VERSION "created by canmatrix"

NS_ :

BS_:

BU_: User ADM_PC_LL25 ADM_PC_BC25 ADM_PC_BP25 ADM_PC_BI25

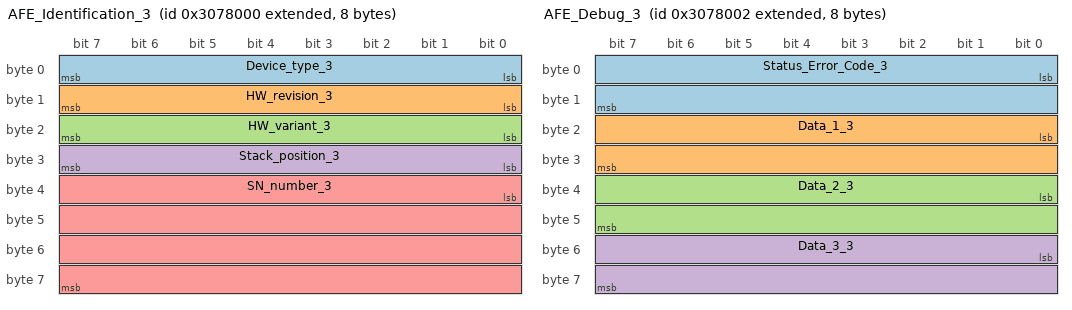
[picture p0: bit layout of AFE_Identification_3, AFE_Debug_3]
BO_ 2198306816 AFE_Identification_3: 8 ADM_PC_BP25
 SG_ Device_type_3 : 0|8@1+ (1,0) [0|255] "" Vector__XXX
 SG_ HW_revision_3 : 8|8@1+ (1,0) [0|255] "" Vector__XXX
 SG_ HW_variant_3 : 16|8@1+ (1,0) [0|255] "" Vector__XXX
 SG_ Stack_position_3 : 24|8@1+ (1,0) [0|255] "" Vector__XXX
 SG_ SN_number_3 : 32|32@1+ (1,0) [0|4294967295] "" Vector__XXX

BO_ 2198306817 AFE_FwInfo_3: 8 ADM_PC_BP25
 SG_ FW_info_mux_3 M : 56|8@1+ (1,0) [0|255] "" Vector__XXX
 SG_ FW_revision_0_3 m0 : 0|8@1+ (1,0) [0|255] "" Vector__XXX
 SG_ FW_revision_1_3 m0 : 8|8@1+ (1,0) [0|255] "" Vector__XXX
 SG_ FW_revision_2_3 m0 : 16|8@1+ (1,0) [0|255] "" Vector__XXX
 SG_ FW_revision_3_3 m0 : 24|8@1+ (1,0) [0|255] "" Vector__XXX
 SG_ FW_revision_4_3 m0 : 32|8@1+ (1,0) [0|255] "" Vector__XXX
 SG_ FW_revision_5_3 m0 : 40|8@1+ (1,0) [0|255] "" Vector__XXX
 SG_ FW_revision_6_3 m0 : 48|8@1+ (1,0) [0|255] "" Vector__XXX
 SG_ FW_revision_7_3 m1 : 0|8@1+ (1,0) [0|255] "" Vector__XXX
 SG_ FW_revision_8_3 m1 : 8|8@1+ (1,0) [0|255] "" Vector__XXX
 SG_ FW_revision_9_3 m1 : 16|8@1+ (1,0) [0|255] "" Vector__XXX
 SG_ FW_revision_10_3 m1 : 24|8@1+ (1,0) [0|255] "" Vector__XXX
 SG_ FW_revision_11_3 m1 : 32|8@1+ (1,0) [0|255] "" Vector__XXX
 SG_ FW_revision_12_3 m1 : 40|8@1+ (1,0) [0|255] "" Vector__XXX
 SG_ FW_revision_13_3 m1 : 48|8@1+ (1,0) [0|255] "" Vector__XXX
 SG_ FW_datecode_0_3 m2 : 0|8@1+ (1,0) [0|255] "" Vector__XXX
 SG_ FW_datecode_1_3 m2 : 8|8@1+ (1,0) [0|255] "" Vector__XXX
 SG_ FW_datecode_2_3 m2 : 16|8@1+ (1,0) [0|255] "" Vector__XXX
 SG_ FW_datecode_3_3 m2 : 24|8@1+ (1,0) [0|255] "" Vector__XXX
 SG_ FW_datecode_4_3 m2 : 32|8@1+ (1,0) [0|255] "" Vector__XXX
 SG_ FW_datecode_5_3 m2 : 40|8@1+ (1,0) [0|255] "" Vector__XXX
 SG_ FW_datecode_6_3 m2 : 48|8@1+ (1,0) [0|255] "" Vector__XXX
 SG_ FW_datecode_7_3 m3 : 0|8@1+ (1,0) [0|255] "" Vector__XXX
 SG_ FW_datecode_8_3 m3 : 8|8@1+ (1,0) [0|255] "" Vector__XXX
 SG_ FW_datecode_9_3 m3 : 16|8@1+ (1,0) [0|255] "" Vector__XXX
 SG_ FW_datecode_10_3 m3 : 24|8@1+ (1,0) [0|255] "" Vector__XXX
 SG_ FW_datecode_11_3 m3 : 32|8@1+ (1,0) [0|255] "" Vector__XXX
 SG_ FW_datecode_12_3 m3 : 40|8@1+ (1,0) [0|255] "" Vector__XXX
 SG_ FW_datecode_13_3 m3 : 48|8@1+ (1,0) [0|255] "" Vector__XXX

BO_ 2198306829 _AFE_Boot_FwInfo_3: 8 ADM_PC_BP25
 SG_ Boot_FW_info_mux_3 M : 56|8@1+ (1,0) [0|255] "" Vector__XXX
 SG_ FW_revision_0_3 m0 : 0|8@1+ (1,0) [0|255] "" Vector__XXX
 SG_ FW_revision_1_3 m0 : 8|8@1+ (1,0) [0|255] "" Vector__XXX
 SG_ FW_revision_2_3 m0 : 16|8@1+ (1,0) [0|255] "" Vector__XXX
 SG_ FW_revision_3_3 m0 : 24|8@1+ (1,0) [0|255] "" Vector__XXX
 SG_ FW_revision_4_3 m0 : 32|8@1+ (1,0) [0|255] "" Vector__XXX
 SG_ FW_revision_5_3 m0 : 40|8@1+ (1,0) [0|255] "" Vector__XXX
 SG_ FW_revision_6_3 m0 : 48|8@1+ (1,0) [0|255] "" Vector__XXX
 SG_ FW_revision_7_3 m1 : 0|8@1+ (1,0) [0|255] "" Vector__XXX
 SG_ FW_revision_8_3 m1 : 8|8@1+ (1,0) [0|255] "" Vector__XXX
 SG_ FW_revision_9_3 m1 : 16|8@1+ (1,0) [0|255] "" Vector__XXX
 SG_ FW_revision_10_3 m1 : 24|8@1+ (1,0) [0|255] "" Vector__XXX
 SG_ FW_revision_11_3 m1 : 32|8@1+ (1,0) [0|255] "" Vector__XXX
 SG_ FW_revision_12_3 m1 : 40|8@1+ (1,0) [0|255] "" Vector__XXX
 SG_ FW_revision_13_3 m1 : 48|8@1+ (1,0) [0|255] "" Vector__XXX
 SG_ FW_datecode_0_3 m2 : 0|8@1+ (1,0) [0|255] "" Vector__XXX
 SG_ FW_datecode_1_3 m2 : 8|8@1+ (1,0) [0|255] "" Vector__XXX
 SG_ FW_datecode_2_3 m2 : 16|8@1+ (1,0) [0|255] "" Vector__XXX
 SG_ FW_datecode_3_3 m2 : 24|8@1+ (1,0) [0|255] "" Vector__XXX
 SG_ FW_datecode_4_3 m2 : 32|8@1+ (1,0) [0|255] "" Vector__XXX
 SG_ FW_datecode_5_3 m2 : 40|8@1+ (1,0) [0|255] "" Vector__XXX
 SG_ FW_datecode_6_3 m2 : 48|8@1+ (1,0) [0|255] "" Vector__XXX
 SG_ FW_datecode_7_3 m3 : 0|8@1+ (1,0) [0|255] "" Vector__XXX
 SG_ FW_datecode_8_3 m3 : 8|8@1+ (1,0) [0|255] "" Vector__XXX
 SG_ FW_datecode_9_3 m3 : 16|8@1+ (1,0) [0|255] "" Vector__XXX
 SG_ FW_datecode_10_3 m3 : 24|8@1+ (1,0) [0|255] "" Vector__XXX
 SG_ FW_datecode_11_3 m3 : 32|8@1+ (1,0) [0|255] "" Vector__XXX
 SG_ FW_datecode_12_3 m3 : 40|8@1+ (1,0) [0|255] "" Vector__XXX
 SG_ FW_datecode_13_3 m3 : 48|8@1+ (1,0) [0|255] "" Vector__XXX

BO_ 2198306818 AFE_Debug_3: 8 ADM_PC_BP25
 SG_ Status_Error_Code_3 : 0|16@1+ (1,0) [0|65535] "" Vector__XXX
 SG_ Data_1_3 : 16|16@1+ (1,0) [0|65535] "" Vector__XXX
 SG_ Data_2_3 : 32|16@1+ (1,0) [0|65535] "" Vector__XXX
 SG_ Data_3_3 : 48|16@1+ (1,0) [0|65535] "" Vector__XXX

BO_ 2198306823 AFE_Status_3: 8 ADM_PC_BP25
 SG_ Running_3 : 0|1@1+ (1,0) [0|1] "" Vector__XXX
 SG_ PWM_3 : 1|1@1+ (1,0) [0|1] "" Vector__XXX
 SG_ Current_dc_loop_mode_3 : 2|1@1+ (1,0) [0|1] "" Vector__XXX
 SG_ Current_ac_loop_mode_3 : 3|1@1+ (1,0) [0|1] "" Vector__XXX
 SG_ Buck_3 : 5|1@1+ (1,0) [0|1] "" Vector__XXX
 SG_ Boost_3 : 6|1@1+ (1,0) [0|1] "" Vector__XXX
 SG_ Precharge_dc_buck_mode_3 : 7|1@1+ (1,0) [0|1] "" Vector__XXX
 SG_ Precharge_dc_boost_mode_3 : 8|1@1+ (1,0) [0|1] "" Vector__XXX
 SG_ Rectifier_3ph_3 : 9|1@1+ (1,0) [0|1] "" Vector__XXX
 SG_ Stack_mode_3 : 10|1@1+ (1,0) [0|1] "" Vector__XXX
 SG_ Master_3 : 11|1@1+ (1,0) [0|1] "" Vector__XXX
 SG_ Slave_3 : 12|1@1+ (1,0) [0|1] "" Vector__XXX
 SG_ Inverter_1ph_3 : 13|1@1+ (1,0) [0|1] "" Vector__XXX
 SG_ Boost_Neutral_3 : 14|1@1+ (1,0) [0|1] "" Vector__XXX
 SG_ Rectifier_1ph_3 : 15|1@1+ (1,0) [0|1] "" Vector__XXX
 SG_ Inverter_3ph_3 : 16|1@1+ (1,0) [0|1] "" Vector__XXX
 SG_ Ready_3 : 17|1@1+ (1,0) [0|1] "" Vector__XXX
 SG_ Inverter_1ph_Sync_3 : 18|1@1+ (1,0) [0|1] "" Vector__XXX
 SG_ Neutral_3 : 19|1@1+ (1,0) [0|1] "" Vector__XXX
 SG_ Rectifier_1ph_Buck_3 : 20|1@1+ (1,0) [0|1] "" Vector__XXX
 SG_ Inverter_1ph_Boost_3 : 21|1@1+ (1,0) [0|1] "" Vector__XXX
 SG_ Rectifier_distributed_3 : 22|1@1+ (1,0) [0|1] "" Vector__XXX
 SG_ MPPT_buck_3 : 23|1@1+ (1,0) [0|1] "" Vector__XXX
 SG_ MPPT_boost_3 : 24|1@1+ (1,0) [0|1] "" Vector__XXX
 SG_ Buck_2p_float_3 : 25|1@1+ (1,0) [0|1] "" Vector__XXX
 SG_ Inverter_1ph_Distributed_3 : 26|1@1+ (1,0) [0|1] "" Vector__XXX

BO_ 2198306822 AFE_Faults_3: 3 ADM_PC_BP25
 SG_ Protection_trip_internal_3 : 0|1@1+ (1,0) [0|1] "" Vector__XXX
 SG_ Protection_trip_external_3 : 1|1@1+ (1,0) [0|1] "" Vector__XXX
 SG_ Phase_U_overcurrent_3 : 2|1@1+ (1,0) [0|1] "" Vector__XXX
 SG_ Phase_U_overvoltage_3 : 3|1@1+ (1,0) [0|1] "" Vector__XXX
 SG_ Phase_U_undervoltage_3 : 4|1@1+ (1,0) [0|1] "" Vector__XXX
 SG_ Phase_V_overvoltage_3 : 5|1@1+ (1,0) [0|1] "" Vector__XXX
 SG_ Phase_V_undervoltage_3 : 6|1@1+ (1,0) [0|1] "" Vector__XXX
 SG_ Phase_V_overcurrent_3 : 7|1@1+ (1,0) [0|1] "" Vector__XXX
 SG_ Phase_W_overvoltage_3 : 8|1@1+ (1,0) [0|1] "" Vector__XXX
 SG_ Phase_W_undervoltage_3 : 9|1@1+ (1,0) [0|1] "" Vector__XXX
 SG_ Phase_W_overcurrent_3 : 10|1@1+ (1,0) [0|1] "" Vector__XXX
 SG_ DC_undervoltage_3 : 11|1@1+ (1,0) [0|1] "" Vector__XXX
 SG_ DC_overvoltage_3 : 12|1@1+ (1,0) [0|1] "" Vector__XXX
 SG_ MOSFET_overtemperature_3 : 13|1@1+ (1,0) [0|1] "" Vector__XXX
 SG_ Inductor_overtemperature_3 : 14|1@1+ (1,0) [0|1] "" Vector__XXX
 SG_ Keep_Alive_not_served_3 : 15|1@1+ (1,0) [0|1] "" Vector__XXX
 SG_ PLL_not_locked_3 : 16|1@1+ (1,0) [0|1] "" Vector__XXX
 SG_ NFO_3 : 20|1@1+ (1,0) [0|1] "" Vector__XXX
 SG_ Measurement_system_failure_3 : 21|1@1+ (1,0) [0|1] "" Vector__XXX
 SG_ EEPROM_failure_3 : 22|1@1+ (1,0) [0|1] "" Vector__XXX
 SG_ System_3 : 23|1@1+ (1,0) [0|1] "" Vector__XXX

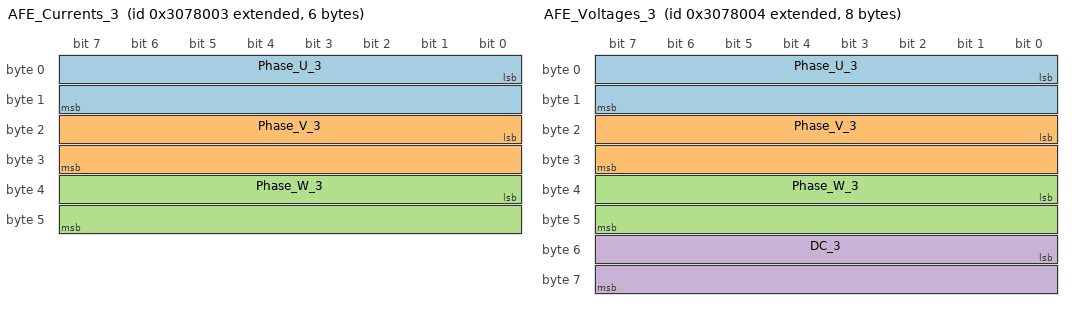
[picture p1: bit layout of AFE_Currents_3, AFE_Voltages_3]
BO_ 2198306819 AFE_Currents_3: 6 ADM_PC_BP25
 SG_ Phase_U_3 : 0|16@1- (0.01,0) [-327.68|327.67] "A" Vector__XXX
 SG_ Phase_V_3 : 16|16@1- (0.01,0) [-327.68|327.67] "A" Vector__XXX
 SG_ Phase_W_3 : 32|16@1- (0.01,0) [-327.68|327.67] "A" Vector__XXX

BO_ 2198306832 AFE_DC_Bus_current_3: 2 ADM_PC_BP25
 SG_ Bus_current_3 : 0|16@1- (0.01,0) [-327.68|327.67] "A" Vector__XXX

BO_ 2198306830 _AFE_Broadcast_3: 8 ADM_PC_BP25
 SG_ Diagnostics_Index_3 M : 56|8@1+ (1,0) [0|255] "" Vector__XXX
 SG_ Phase_U_3 m1 : 8|16@1- (0.01,0) [-327.68|327.67] "A" ADM_PC_BP25
 SG_ Phase_V_3 m1 : 24|16@1- (0.01,0) [-327.68|327.67] "A" ADM_PC_BP25
 SG_ Phase_W_3 m1 : 40|16@1- (0.01,0) [-327.68|327.67] "A" ADM_PC_BP25
 SG_ Stack_position_3 : 0|5@1+ (1,0) [0|31] "" ADM_PC_BP25
 SG_ Group_ID_3 : 5|3@1+ (1,0) [0|7] "" ADM_PC_BP25

BO_ 2198306820 AFE_Voltages_3: 8 ADM_PC_BP25
 SG_ Phase_U_3 : 0|16@1- (0.1,0) [-3276.8|3276.7] "V" Vector__XXX
 SG_ Phase_V_3 : 16|16@1- (0.1,0) [-3276.8|3276.7] "V" Vector__XXX
 SG_ Phase_W_3 : 32|16@1- (0.1,0) [-3276.8|3276.7] "V" Vector__XXX
 SG_ DC_3 : 48|16@1- (0.1,0) [-3276.8|3276.7] "V" Vector__XXX

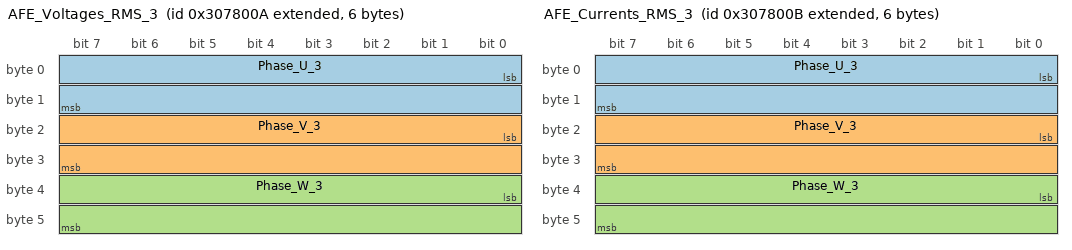
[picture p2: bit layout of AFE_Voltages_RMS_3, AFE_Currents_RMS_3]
BO_ 2198306826 AFE_Voltages_RMS_3: 6 ADM_PC_BP25
 SG_ Phase_U_3 : 0|16@1+ (0.1,0) [0|6553.5] "V" Vector__XXX
 SG_ Phase_V_3 : 16|16@1+ (0.1,0) [0|6553.5] "V" Vector__XXX
 SG_ Phase_W_3 : 32|16@1+ (0.1,0) [0|6553.5] "V" Vector__XXX

BO_ 2198306827 AFE_Currents_RMS_3: 6 ADM_PC_BP25
 SG_ Phase_U_3 : 0|16@1+ (0.01,0) [0.00|655.35] "A" Vector__XXX
 SG_ Phase_V_3 : 16|16@1+ (0.01,0) [0.00|655.35] "A" Vector__XXX
 SG_ Phase_W_3 : 32|16@1+ (0.01,0) [0.00|655.35] "A" Vector__XXX

BO_ 2198306828 AFE_Mains_3: 4 ADM_PC_BP25
 SG_ Frequency_3 : 0|16@1+ (0.01,0) [0.00|655.35] "Hz" Vector__XXX
 SG_ Phase_3 : 16|16@1- (0.1,0) [-3276.8|3276.7] "Deg." Vector__XXX

BO_ 2198306821 AFE_Temperatures_3: 4 ADM_PC_BP25
 SG_ Temp_Bridge_3 : 0|16@1- (0.01,0) [-327.68|327.67] "°C" Vector__XXX
 SG_ Temp_Inductors_3 : 16|16@1- (0.01,0) [-327.68|327.67] "°C" Vector__XXX

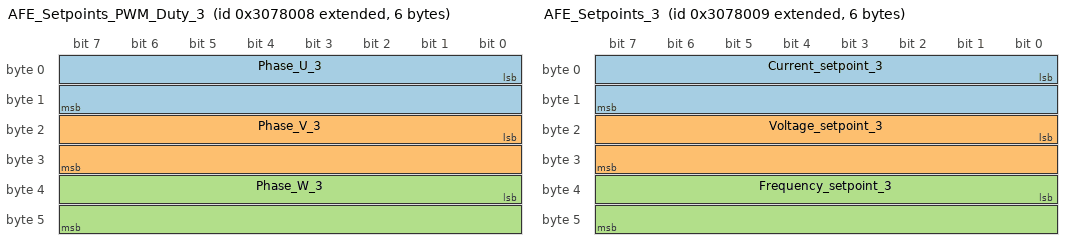
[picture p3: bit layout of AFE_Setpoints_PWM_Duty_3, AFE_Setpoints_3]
BO_ 2198306824 AFE_Setpoints_PWM_Duty_3: 6 ADM_PC_BP25
 SG_ Phase_U_3 : 0|16@1+ (0.001525902,0) [0E-009|99.999987570] "%" Vector__XXX
 SG_ Phase_V_3 : 16|16@1+ (0.001525902,0) [0E-009|99.999987570] "%" Vector__XXX
 SG_ Phase_W_3 : 32|16@1+ (0.001525902,0) [0E-009|99.999987570] "%" Vector__XXX

BO_ 2198306825 AFE_Setpoints_3: 6 ADM_PC_BP25
 SG_ Current_setpoint_3 : 0|16@1- (0.01,0) [-327.68|327.67] "A" Vector__XXX
 SG_ Voltage_setpoint_3 : 16|16@1+ (0.1,0) [0|6553.5] "V" Vector__XXX
 SG_ Frequency_setpoint_3 : 32|16@1+ (0.01,0) [0.00|655.35] "Hz" Vector__XXX

BO_ 2198274144 AFE_Keep_Alive_3: 1 User
 SG_ Keep_Alive_Enable_3 : 0|1@1+ (1,0) [0|1] "" ADM_PC_BP25

BO_ 2198274112 AFE_Mode_Control_3: 8 User
 SG_ Converter_ON_3 : 0|1@1+ (1,0) [0|1] "" ADM_PC_BP25
 SG_ PWM_ON_3 : 1|1@1+ (1,0) [0|1] "" ADM_PC_BP25
 SG_ DC_Current_feedback_ON_3 : 2|1@1+ (1,0) [0|1] "" ADM_PC_BP25
 SG_ AC_Current_feedback_ON_3 : 3|1@1+ (1,0) [0|1] "" ADM_PC_BP25
 SG_ Buck_ON_3 : 5|1@1+ (1,0) [0|1] "" ADM_PC_BP25
 SG_ Boost_ON_3 : 6|1@1+ (1,0) [0|1] "" ADM_PC_BP25
 SG_ Rectifier_3ph_ON_3 : 9|1@1+ (1,0) [0|1] "" ADM_PC_BP25
 SG_ Inverter_1ph_ON_3 : 10|1@1+ (1,0) [0|1] "" ADM_PC_BP25
 SG_ Rectifier_1ph_ON_3 : 11|1@1+ (1,0) [0|1] "" ADM_PC_BP25
 SG_ Boost_Neutral_ON_3 : 12|1@1+ (1,0) [0|1] "" ADM_PC_BP25
 SG_ Inverter_3ph_ON_3 : 13|1@1+ (1,0) [0|1] "" ADM_PC_BP25
 SG_ Inverter_1ph_Sync_ON_3 : 14|1@1+ (1,0) [0|1] "" ADM_PC_BP25
 SG_ Neutral_ON_3 : 15|1@1+ (1,0) [0|1] "" ADM_PC_BP25
 SG_ Rectifier_1ph_Buck_ON_3 : 16|1@1+ (1,0) [0|1] "" ADM_PC_BP25
 SG_ Inverter_1ph_Boost_ON_3 : 17|1@1+ (1,0) [0|1] "" ADM_PC_BP25
 SG_ Rectifier_Distributed_ON_3 : 18|1@1+ (1,0) [0|1] "" ADM_PC_BP25
 SG_ MPPT_buck_ON_3 : 19|1@1+ (1,0) [0|1] "" ADM_PC_BP25
 SG_ MPPT_boost_ON_3 : 20|1@1+ (1,0) [0|1] "" ADM_PC_BP25
 SG_ Buck_2p_float_ON_3 : 21|1@1+ (1,0) [0|1] "" ADM_PC_BP25
 SG_ Inverter_1ph_Distributed_ON_3 : 22|1@1+ (1,0) [0|1] "" ADM_PC_BP25

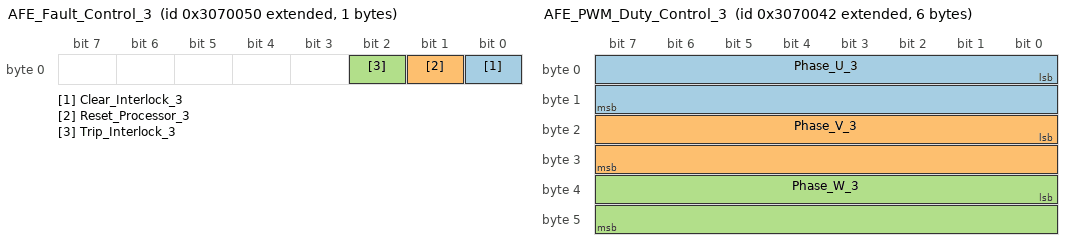
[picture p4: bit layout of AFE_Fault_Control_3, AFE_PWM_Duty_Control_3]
BO_ 2198274128 AFE_Fault_Control_3: 1 User
 SG_ Clear_Interlock_3 : 0|1@1+ (1,0) [0|1] "" ADM_PC_BP25
 SG_ Reset_Processor_3 : 1|1@1+ (1,0) [0|1] "" ADM_PC_BP25
 SG_ Trip_Interlock_3 : 2|1@1+ (1,0) [0|1] "" ADM_PC_BP25

BO_ 2198274113 AFE_Reactive_Current_Setpoint_Co: 2 User
 SG_ Reactive_current_setpoint_3 : 0|16@1- (0.01,0) [-150|150] "A" ADM_PC_BP25

BO_ 2198274114 AFE_PWM_Duty_Control_3: 6 User
 SG_ Phase_U_3 : 0|16@1+ (0.001525902,0) [0E-009|99.999987570] "%" ADM_PC_BP25
 SG_ Phase_V_3 : 16|16@1+ (0.001525902,0) [0E-009|99.999987570] "%" ADM_PC_BP25
 SG_ Phase_W_3 : 32|16@1+ (0.001525902,0) [0E-009|99.999987570] "%" ADM_PC_BP25

BO_ 2198274115 AFE_Current_Setpoint_Control_3: 2 User
 SG_ Current_setpoint_3 : 0|16@1- (0.01,0) [-150|150] "A" ADM_PC_BP25

BO_ 2198274116 AFE_Voltage_Setpoint_Control_3: 2 User
 SG_ Voltage_setpoint_3 : 0|16@1+ (0.1,0) [0|1500] "V" ADM_PC_BP25

BO_ 2198274120 AFE_Frequency_Setpoint_Control_3: 2 User
 SG_ Frequency_setpoint_3 : 0|16@1+ (0.01,0) [40|70] "Hz" ADM_PC_BP25

BO_ 2198274121 AFE_Phase_Setpoint_Control_3: 2 User
 SG_ Phase_setpoint_3 : 0|16@1+ (1,0) [0|360] "deg" ADM_PC_BP25

BO_ 2198274160 AFE_Rectifier_Setpoint_Control_3: 8 User
 SG_ Voltage_setpoint_2_3 : 0|16@1+ (0.1,0) [0|1500] "V" ADM_PC_BP25
 SG_ Current_setpoint_2_3 : 16|16@1- (0.01,0) [-150|150] "A" ADM_PC_BP25

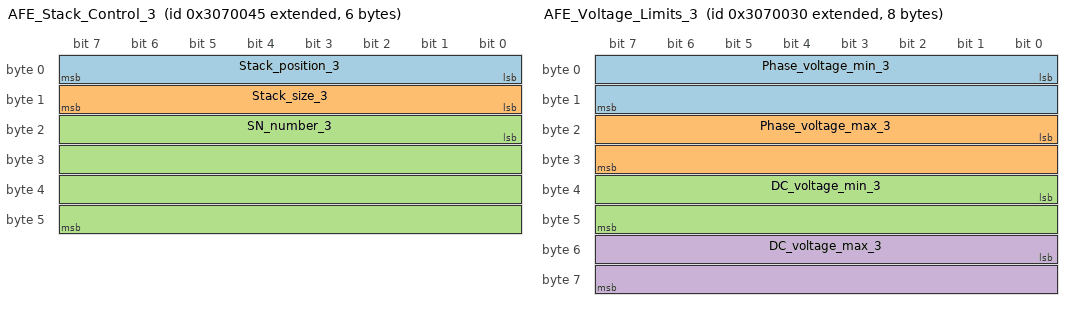
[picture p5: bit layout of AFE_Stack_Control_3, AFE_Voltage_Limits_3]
BO_ 2198274117 AFE_Stack_Control_3: 6 User
 SG_ Stack_position_3 : 0|8@1+ (1,0) [0|255] "" ADM_PC_BP25
 SG_ Stack_size_3 : 8|8@1+ (1,0) [0|255] "" ADM_PC_BP25
 SG_ SN_number_3 : 16|32@1+ (1,0) [0|4294967295] "" ADM_PC_BP25

BO_ 2198274096 AFE_Voltage_Limits_3: 8 User
 SG_ Phase_voltage_min_3 : 0|16@1- (0.1,0) [0|3276.7] "V" ADM_PC_BP25
 SG_ Phase_voltage_max_3 : 16|16@1- (0.1,0) [-3276.8|850] "V" ADM_PC_BP25
 SG_ DC_voltage_min_3 : 32|16@1- (0.1,0) [0|3276.7] "V" ADM_PC_BP25
 SG_ DC_voltage_max_3 : 48|16@1- (0.1,0) [-3276.8|850] "V" ADM_PC_BP25

BO_ 2198274097 AFE_Current_Limits_3: 4 User
 SG_ Phase_current_min_3 : 0|16@1- (0.01,0) [-60|60] "A" ADM_PC_BP25
 SG_ Phase_current_max_3 : 16|16@1- (0.01,0) [-60|60] "A" ADM_PC_BP25

BO_ 2198274124 AFE_Group_Control_3: 1 User
 SG_ Group_ID_3 : 0|8@1+ (1,0) [0|255] "" ADM_PC_BP25

BO_ 2198306831 AFE_Group_Info_3: 1 ADM_PC_BP25
 SG_ Group_ID_3 : 0|8@1+ (1,0) [0|255] "" Vector__XXX

BO_ 2198274145 AFE_System_Flags_Control_3: 8 User
 SG_ Factory_mode_3 : 0|1@1+ (1,0) [0|1] "" ADM_PC_BP25
 SG_ Silent_CAN_mode_3 : 1|1@1+ (1,0) [0|1] "" ADM_PC_BP25

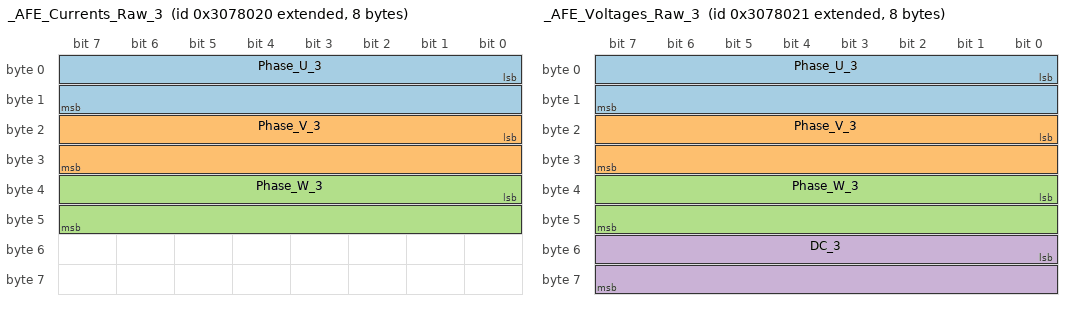
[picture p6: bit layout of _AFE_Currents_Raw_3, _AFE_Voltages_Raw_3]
BO_ 2198306848 _AFE_Currents_Raw_3: 8 ADM_PC_BP25
 SG_ Phase_U_3 : 0|16@1- (1,0) [-32768|32767] "" Vector__XXX
 SG_ Phase_V_3 : 16|16@1- (1,0) [-32768|32767] "" Vector__XXX
 SG_ Phase_W_3 : 32|16@1- (1,0) [-32768|32767] "" Vector__XXX

BO_ 2198306849 _AFE_Voltages_Raw_3: 8 ADM_PC_BP25
 SG_ Phase_U_3 : 0|16@1- (1,0) [-32768|32767] "" Vector__XXX
 SG_ Phase_V_3 : 16|16@1- (1,0) [-32768|32767] "" Vector__XXX
 SG_ Phase_W_3 : 32|16@1- (1,0) [-32768|32767] "" Vector__XXX
 SG_ DC_3 : 48|16@1- (1,0) [-32768|32767] "" Vector__XXX

BO_ 2198274122 _AFE_ADC_Calibration_Mode_3: 1 User
 SG_ Calibration_Index_3 M : 2|5@1+ (1,0) [0|31] "" Vector__XXX
 SG_ Current_U_3 m1 : 0|2@1+ (1,0) [0|3] "" ADM_PC_BP25
 SG_ Current_V_3 m2 : 0|2@1+ (1,0) [0|3] "" ADM_PC_BP25
 SG_ Current_W_3 m3 : 0|2@1+ (1,0) [0|3] "" ADM_PC_BP25
 SG_ Voltage_U_3 m4 : 0|2@1+ (1,0) [0|3] "" ADM_PC_BP25
 SG_ Voltage_V_3 m5 : 0|2@1+ (1,0) [0|3] "" ADM_PC_BP25
 SG_ Voltage_W_3 m6 : 0|2@1+ (1,0) [0|3] "" ADM_PC_BP25
 SG_ Voltage_DC_3 m7 : 0|2@1+ (1,0) [0|3] "" ADM_PC_BP25
 SG_ start_3 : 7|1@1+ (1,0) [0|1] "" ADM_PC_BP25

BO_ 2198274123 _AFE_ADC_Calibration_Setpoint_3: 3 User
 SG_ Calibration_Index_3 M : 16|5@1+ (1,0) [0|31] "" Vector__XXX
 SG_ Current_U_3 m1 : 0|16@1- (0.01,0) [-100|100] "A" ADM_PC_BP25
 SG_ Current_V_3 m2 : 0|16@1- (0.01,0) [-100|100] "A" ADM_PC_BP25
 SG_ Current_W_3 m3 : 0|16@1- (0.01,0) [-100|100] "A" ADM_PC_BP25
 SG_ Voltage_U_3 m4 : 0|16@1+ (0.1,0) [0|1500] "V" ADM_PC_BP25
 SG_ Voltage_V_3 m5 : 0|16@1+ (0.1,0) [0|1500] "V" ADM_PC_BP25
 SG_ Voltage_W_3 m6 : 0|16@1+ (0.1,0) [0|1500] "V" ADM_PC_BP25
 SG_ Voltage_DC_3 m7 : 0|16@1+ (0.1,0) [0|1500] "V" ADM_PC_BP25
 SG_ point_3 : 21|3@1+ (1,0) [0|7] "" ADM_PC_BP25

BO_ 2198274118 _AFE_Calibration_Offset_Update_3: 6 User
 SG_ Calibration_Index_3 M : 16|16@1+ (1,0) [0|65535] "" Vector__XXX
 SG_ Current_U_3 m0 : 0|16@1- (1,0) [-32768|32767] "ADC Counts" ADM_PC_BP25
 SG_ Current_V_3 m1 : 0|16@1- (1,0) [-32768|32767] "ADC Counts" ADM_PC_BP25
 SG_ Current_W_3 m2 : 0|16@1- (1,0) [-32768|32767] "ADC Counts" ADM_PC_BP25
 SG_ Voltage_U_3 m3 : 0|16@1- (1,0) [-32768|32767] "ADC Counts" ADM_PC_BP25
 SG_ Voltage_V_3 m4 : 0|16@1- (1,0) [-32768|32767] "ADC Counts" ADM_PC_BP25
 SG_ Voltage_W_3 m5 : 0|16@1- (1,0) [-32768|32767] "ADC Counts" ADM_PC_BP25
 SG_ Voltage_DC_3 m6 : 0|16@1- (1,0) [-32768|32767] "ADC Counts" ADM_PC_BP25
 SG_ CRC_3 : 32|16@1+ (1,0) [0|65535] "-" ADM_PC_BP25

BO_ 2198274119 _AFE_Calibration_Scale_Update_3: 6 User
 SG_ Calibration_Index_3 M : 16|16@1+ (1,0) [0|65535] "" Vector__XXX
 SG_ Current_U_3 m0 : 0|16@1- (0.0000152587890625,0) [-0.5000000000000000|0.4999847412109375] "scale = 1.0 + value" ADM_PC_BP25
 SG_ Current_V_3 m1 : 0|16@1- (0.0000152587890625,0) [-0.5000000000000000|0.4999847412109375] "scale = 1.0 + value" ADM_PC_BP25
 SG_ Current_W_3 m2 : 0|16@1- (0.0000152587890625,0) [-0.5000000000000000|0.4999847412109375] "scale = 1.0 + value" ADM_PC_BP25
 SG_ Voltage_U_3 m3 : 0|16@1- (0.0000152587890625,0) [-0.5000000000000000|0.4999847412109375] "scale = 1.0 + value" ADM_PC_BP25
 SG_ Voltage_V_3 m4 : 0|16@1- (0.0000152587890625,0) [-0.5000000000000000|0.4999847412109375] "scale = 1.0 + value" ADM_PC_BP25
 SG_ Voltage_W_3 m5 : 0|16@1- (0.0000152587890625,0) [-0.5000000000000000|0.4999847412109375] "scale = 1.0 + value" ADM_PC_BP25
 SG_ Voltage_DC_3 m6 : 0|16@1- (0.0000152587890625,0) [-0.5000000000000000|0.4999847412109375] "scale = 1.0 + value" ADM_PC_BP25
 SG_ CRC_3 : 32|16@1+ (1,0) [0|65535] "-" ADM_PC_BP25

BO_ 2198306897 _AFE_Calibration_Adc_Scale_3: 6 ADM_PC_BP25
 SG_ Adc_Index_3 M : 32|16@1+ (1,0) [0|65535] "" Vector__XXX
 SG_ Current_U_3 m0 : 0|32@1+ (1,0) [0|4294967295] "1 / adc_bins" User
 SG_ Current_V_3 m1 : 0|32@1+ (1,0) [0|4294967295] "1 / adc_bins" User
 SG_ Current_W_3 m2 : 0|32@1+ (1,0) [0|4294967295] "1 / adc_bins" User
 SG_ Voltage_U_3 m3 : 0|32@1+ (1,0) [0|4294967295] "1 / adc_bins" User
 SG_ Voltage_V_3 m4 : 0|32@1+ (1,0) [0|4294967295] "1 / adc_bins" User
 SG_ Voltage_W_3 m5 : 0|32@1+ (1,0) [0|4294967295] "1 / adc_bins" User
 SG_ Voltage_DC_3 m6 : 0|32@1+ (1,0) [0|4294967295] "1 / adc_bins" User

BO_ 2198306898 _AFE_Calibration_Adc_Fs_3: 6 ADM_PC_BP25
 SG_ Adc_Index_3 M : 32|16@1+ (1,0) [0|65535] "" Vector__XXX
 SG_ Current_U_3 m0 : 0|32@1+ (1,0) [0|4294967295] "Fullscale" User
 SG_ Current_V_3 m1 : 0|32@1+ (1,0) [0|4294967295] "Fullscale" User
 SG_ Current_W_3 m2 : 0|32@1+ (1,0) [0|4294967295] "Fullscale" User
 SG_ Voltage_U_3 m3 : 0|32@1+ (1,0) [0|4294967295] "Fullscale" User
 SG_ Voltage_V_3 m4 : 0|32@1+ (1,0) [0|4294967295] "Fullscale" User
 SG_ Voltage_W_3 m5 : 0|32@1+ (1,0) [0|4294967295] "Fullscale" User
 SG_ Voltage_DC_3 m6 : 0|32@1+ (1,0) [0|4294967295] "Fullscale" User

BO_ 2198306899 _AFE_Calibration_Adc_Offset_3: 4 ADM_PC_BP25
 SG_ Adc_Index_3 M : 16|16@1+ (1,0) [0|65535] "" Vector__XXX
 SG_ Current_U_3 m0 : 0|16@1- (1,0) [-32768|32767] "-" User
 SG_ Current_V_3 m1 : 0|16@1- (1,0) [-32768|32767] "-" User
 SG_ Current_W_3 m2 : 0|16@1- (1,0) [-32768|32767] "-" User
 SG_ Voltage_U_3 m3 : 0|16@1- (1,0) [-32768|32767] "-" User
 SG_ Voltage_V_3 m4 : 0|16@1- (1,0) [-32768|32767] "-" User
 SG_ Voltage_W_3 m5 : 0|16@1- (1,0) [-32768|32767] "-" User
 SG_ Voltage_DC_3 m6 : 0|16@1- (1,0) [-32768|32767] "-" User

BO_ 2198306900 _AFE_Calibration_Adc_Gain_3: 4 ADM_PC_BP25
 SG_ Adc_Index_3 M : 16|16@1+ (1,0) [0|65535] "" Vector__XXX
 SG_ Current_U_3 m0 : 0|16@1- (1,0) [-32768|32767] "-" User
 SG_ Current_V_3 m1 : 0|16@1- (1,0) [-32768|32767] "-" User
 SG_ Current_W_3 m2 : 0|16@1- (1,0) [-32768|32767] "-" User
 SG_ Voltage_U_3 m3 : 0|16@1- (1,0) [-32768|32767] "-" User
 SG_ Voltage_V_3 m4 : 0|16@1- (1,0) [-32768|32767] "-" User
 SG_ Voltage_W_3 m5 : 0|16@1- (1,0) [-32768|32767] "-" User
 SG_ Voltage_DC_3 m6 : 0|16@1- (1,0) [-32768|32767] "-" User

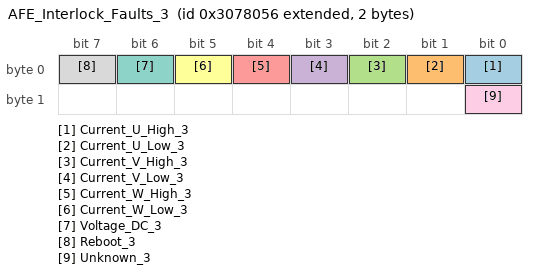
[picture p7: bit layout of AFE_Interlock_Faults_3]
BO_ 2198306902 AFE_Interlock_Faults_3: 2 ADM_PC_BP25
 SG_ Current_U_High_3 : 0|1@1+ (1,0) [0|1] "" Vector__XXX
 SG_ Current_U_Low_3 : 1|1@1+ (1,0) [0|1] "" Vector__XXX
 SG_ Current_V_High_3 : 2|1@1+ (1,0) [0|1] "" Vector__XXX
 SG_ Current_V_Low_3 : 3|1@1+ (1,0) [0|1] "" Vector__XXX
 SG_ Current_W_High_3 : 4|1@1+ (1,0) [0|1] "" Vector__XXX
 SG_ Current_W_Low_3 : 5|1@1+ (1,0) [0|1] "" Vector__XXX
 SG_ Voltage_DC_3 : 6|1@1+ (1,0) [0|1] "" Vector__XXX
 SG_ Reboot_3 : 7|1@1+ (1,0) [0|1] "" Vector__XXX
 SG_ Unknown_3 : 8|1@1+ (1,0) [0|1] "" Vector__XXX

BO_TX_BU_ 2198274112 : User,ADM_PC_LL25,ADM_PC_BC25,ADM_PC_BI25;
BO_TX_BU_ 2198274115 : User,ADM_PC_LL25,ADM_PC_BC25,ADM_PC_BI25;
BO_TX_BU_ 2198274116 : User,ADM_PC_LL25,ADM_PC_BC25,ADM_PC_BI25;
CM_ BO_ 2198306816  "Identification of the device";
CM_ BO_ 2198306817  "Git revision of the DSP firmware";
CM_ BO_ 2198306829  "Git revision of the bootloader firmware.";
CM_ BO_ 2198306818  "Values for debugging of HW/SW problems";
CM_ BO_ 2198306823  "Status bitfield";
CM_ BO_ 2198306822  "Fault bitfield";
CM_ BO_ 2198306819  "Current of phases U, V, W";
CM_ BO_ 2198306832  "Current of of the DC Bus";
CM_ BO_ 2198306830  "All AFEs will listen to this message";
CM_ BO_ 2198306827  "RMS Current of phases U, V, W";
CM_ BO_ 2198306828  "Three-Phase mains health (frequency, phase...)";
CM_ BO_ 2198306821  "Readouts of the module temperature sensors";
CM_ BO_ 2198306824  "Setpoints";
CM_ BO_ 2198306825  "Setpoints";
CM_ BO_ 2198274144  "Keep alive ping message. ";
CM_ BO_ 2198274112  "Operation Mode control: sets the converter operation mode";
CM_ BO_ 2198274128  "Fault Control: actions to clear faults and reset the system";
CM_ BO_ 2198274113  "Reactive power setpoint control.";
CM_ BO_ 2198274114  "PWM duty cycle control";
CM_ BO_ 2198274115  "Current setpoint control";
CM_ BO_ 2198274116  "Voltage setpoint control";
CM_ BO_ 2198274120  "Frequency setpoint control";
CM_ BO_ 2198274121  "Phase setpoint control";
CM_ BO_ 2198274160  "Additional voltage and current setpoints in single-phase rectifier and inverter control modes.";
CM_ BO_ 2198274117  "PFC stack control";
CM_ BO_ 2198274096  "Set the input and output voltage limits (minimum and maximum)";
CM_ BO_ 2198274097  "Set the output current limits (mminimum and maximum)";
CM_ BO_ 2198274124  "Set the Group ID of the device";
CM_ BO_ 2198306831  "Contains the Group ID of the device";
CM_ BO_ 2198274145  "Control the system flags";
CM_ BO_ 2198306848  "Current of phases A and B";
CM_ BO_ 2198306849  "Current of phases A and B";
CM_ BO_ 2198274122  "Automatic ADC calibration.";
CM_ BO_ 2198274123  "Setpoint for automatic ADC calibration.";
CM_ BO_ 2198274118  "Update of the calibration table for offsets.";
CM_ BO_ 2198274119  "Update of the calibration table for scales.";
CM_ BO_ 2198306897  "
                Adc scale (resolution) value of readouts.
            ";
CM_ BO_ 2198306898  "
                Adc fullscale value of readouts.
            ";
CM_ BO_ 2198306899  "
                Readout of ADC calibration data (offset) from EEPROM.
            ";
CM_ BO_ 2198306900  "
                Readout of ADC calibration data (gain) from EEPROM.
            ";
CM_ BO_ 2198306902  "Fault bitfield";

CM_ SG_ 2198306816 Device_type_3 "The device identification field, uniquely identifies the sender in the network";
CM_ SG_ 2198306816 HW_revision_3 "The hardware revision number";
CM_ SG_ 2198306816 HW_variant_3 "The DSP firmware revision number";
CM_ SG_ 2198306816 Stack_position_3 "Position of the module within the stack";
CM_ SG_ 2198306816 SN_number_3 "Unique module serial number";
CM_ SG_ 2198306817 FW_revision_0_3 "Character 0";
CM_ SG_ 2198306817 FW_revision_1_3 "Character 1";
CM_ SG_ 2198306817 FW_revision_2_3 "Character 2";
CM_ SG_ 2198306817 FW_revision_3_3 "Character 3";
CM_ SG_ 2198306817 FW_revision_4_3 "Character 3";
CM_ SG_ 2198306817 FW_revision_5_3 "Character 3";
CM_ SG_ 2198306817 FW_revision_6_3 "Character 3";
CM_ SG_ 2198306817 FW_revision_7_3 "Character 7";
CM_ SG_ 2198306817 FW_revision_8_3 "Character 8";
CM_ SG_ 2198306817 FW_revision_9_3 "Character 9";
CM_ SG_ 2198306817 FW_revision_10_3 "Character 10";
CM_ SG_ 2198306817 FW_revision_11_3 "Character 11";
CM_ SG_ 2198306817 FW_revision_12_3 "Character 12";
CM_ SG_ 2198306817 FW_revision_13_3 "Character 13";
CM_ SG_ 2198306817 FW_datecode_0_3 "Character 0";
CM_ SG_ 2198306817 FW_datecode_1_3 "Character 1";
CM_ SG_ 2198306817 FW_datecode_2_3 "Character 2";
CM_ SG_ 2198306817 FW_datecode_3_3 "Character 3";
CM_ SG_ 2198306817 FW_datecode_4_3 "Character 3";
CM_ SG_ 2198306817 FW_datecode_5_3 "Character 3";
CM_ SG_ 2198306817 FW_datecode_6_3 "Character 3";
CM_ SG_ 2198306817 FW_datecode_7_3 "Character 7";
CM_ SG_ 2198306817 FW_datecode_8_3 "Character 8";
CM_ SG_ 2198306817 FW_datecode_9_3 "Character 9";
CM_ SG_ 2198306817 FW_datecode_10_3 "Character 10";
CM_ SG_ 2198306817 FW_datecode_11_3 "Character 11";
CM_ SG_ 2198306817 FW_datecode_12_3 "Character 12";
CM_ SG_ 2198306817 FW_datecode_13_3 "Character 13";
CM_ SG_ 2198306829 FW_revision_0_3 "Character 0";
CM_ SG_ 2198306829 FW_revision_1_3 "Character 1";
CM_ SG_ 2198306829 FW_revision_2_3 "Character 2";
CM_ SG_ 2198306829 FW_revision_3_3 "Character 3";
CM_ SG_ 2198306829 FW_revision_4_3 "Character 3";
CM_ SG_ 2198306829 FW_revision_5_3 "Character 3";
CM_ SG_ 2198306829 FW_revision_6_3 "Character 3";
CM_ SG_ 2198306829 FW_revision_7_3 "Character 7";
CM_ SG_ 2198306829 FW_revision_8_3 "Character 8";
CM_ SG_ 2198306829 FW_revision_9_3 "Character 9";
CM_ SG_ 2198306829 FW_revision_10_3 "Character 10";
CM_ SG_ 2198306829 FW_revision_11_3 "Character 11";
CM_ SG_ 2198306829 FW_revision_12_3 "Character 12";
CM_ SG_ 2198306829 FW_revision_13_3 "Character 13";
CM_ SG_ 2198306829 FW_datecode_0_3 "Character 0";
CM_ SG_ 2198306829 FW_datecode_1_3 "Character 1";
CM_ SG_ 2198306829 FW_datecode_2_3 "Character 2";
CM_ SG_ 2198306829 FW_datecode_3_3 "Character 3";
CM_ SG_ 2198306829 FW_datecode_4_3 "Character 3";
CM_ SG_ 2198306829 FW_datecode_5_3 "Character 3";
CM_ SG_ 2198306829 FW_datecode_6_3 "Character 3";
CM_ SG_ 2198306829 FW_datecode_7_3 "Character 7";
CM_ SG_ 2198306829 FW_datecode_8_3 "Character 8";
CM_ SG_ 2198306829 FW_datecode_9_3 "Character 9";
CM_ SG_ 2198306829 FW_datecode_10_3 "Character 10";
CM_ SG_ 2198306829 FW_datecode_11_3 "Character 11";
CM_ SG_ 2198306829 FW_datecode_12_3 "Character 12";
CM_ SG_ 2198306829 FW_datecode_13_3 "Character 13";
CM_ SG_ 2198306818 Status_Error_Code_3 "Main status / error code as defined in errno/errno.h";
CM_ SG_ 2198306818 Data_1_3 "Additional information for the error/status";
CM_ SG_ 2198306818 Data_2_3 "Additional information for the error/status";
CM_ SG_ 2198306818 Data_3_3 "Additional information for the error/status";
CM_ SG_ 2198306823 Running_3 "Indicates if converter is running.";
CM_ SG_ 2198306823 PWM_3 "Indicates if converter is in PWM control mode.";
CM_ SG_ 2198306823 Current_dc_loop_mode_3 "Indicates if the current DC loop is enabled.";
CM_ SG_ 2198306823 Current_ac_loop_mode_3 "Indicates if the current AC loop is enabled.";
CM_ SG_ 2198306823 Buck_3 "Indicates if converter is in buck control mode.";
CM_ SG_ 2198306823 Boost_3 "Indicates if converter is in boost control mode.";
CM_ SG_ 2198306823 Precharge_dc_buck_mode_3 "Indicates if the precharge DC mode is enabled - buck direction.";
CM_ SG_ 2198306823 Precharge_dc_boost_mode_3 "Indicates if the precharge DC mode is enabled - boost direction.";
CM_ SG_ 2198306823 Rectifier_3ph_3 "Indicates if converter is in three-phase rectifier control mode.";
CM_ SG_ 2198306823 Stack_mode_3 "Indicates if converter is operating in stack mode.";
CM_ SG_ 2198306823 Master_3 "Indicates if converter is master in the stack.";
CM_ SG_ 2198306823 Slave_3 "Indicates if converter is slave in the stack.";
CM_ SG_ 2198306823 Inverter_1ph_3 "Indicates if converter is in single-phase inverter control mode.";
CM_ SG_ 2198306823 Boost_Neutral_3 "Indicates if converter is in boost control mode with neutral generation.";
CM_ SG_ 2198306823 Rectifier_1ph_3 "Indicates if converter is in single-phase rectifier control mode.";
CM_ SG_ 2198306823 Inverter_3ph_3 "Indicates if converter is in three-phase inverter control mode.";
CM_ SG_ 2198306823 Ready_3 "Indicates if converter is ready for operation.";
CM_ SG_ 2198306823 Inverter_1ph_Sync_3 "Single-phase inverter control mode with phase synchronization.";
CM_ SG_ 2198306823 Neutral_3 "Open-loop neutral generation.";
CM_ SG_ 2198306823 Rectifier_1ph_Buck_3 "Single-phase rectifier with buck on one leg.";
CM_ SG_ 2198306823 Inverter_1ph_Boost_3 "Single-phase inverter with boost on one leg.";
CM_ SG_ 2198306823 Rectifier_distributed_3 "Not available at the moment";
CM_ SG_ 2198306823 MPPT_buck_3 "Not available at the moment";
CM_ SG_ 2198306823 MPPT_boost_3 "Not available at the moment";
CM_ SG_ 2198306823 Buck_2p_float_3 "Buck in phases L1 and L2. Phase L3 is left floating (high impedance)";
CM_ SG_ 2198306823 Inverter_1ph_Distributed_3 "Single-phase inverter mode  distributed";
CM_ SG_ 2198306822 Protection_trip_internal_3 "This flagg is asserted if the interlock is open due to an internal fault condition (self-protection)";
CM_ SG_ 2198306822 Protection_trip_external_3 "This flag is asserted if the interlock is open due to an external condition received in the module.";
CM_ SG_ 2198306822 Phase_U_overcurrent_3 "Indicates an overcurrent event on Phase U. The overcurrent event is triggered when the measured phase current is over the programmed current limit.";
CM_ SG_ 2198306822 Phase_U_overvoltage_3 "Indicates an overvoltage event on Phase U. The overvoltage event is triggered when the measured phase voltage is over the programmed voltage limit.";
CM_ SG_ 2198306822 Phase_U_undervoltage_3 "Indicates an undervoltage event on Phase U. The overvoltage event is triggered when the measured phase voltage is over the programmed voltage limit.";
CM_ SG_ 2198306822 Phase_V_overvoltage_3 "Indicates an overvoltage event on Phase V. The overvoltage event is triggered when the measured phase voltage is over the programmed voltage limit.";
CM_ SG_ 2198306822 Phase_V_undervoltage_3 "Indicates an undervoltage event on Phase U. The overvoltage event is triggered when the measured phase voltage is over the programmed voltage limit.";
CM_ SG_ 2198306822 Phase_V_overcurrent_3 "Indicates an overcurrent event on Phase U. The overcurrent event is triggered when the measured phase current is over the programmed current limit.";
CM_ SG_ 2198306822 Phase_W_overvoltage_3 "Indicates an overvoltage event on Phase U. The overvoltage event is triggered when the measured phase voltage is over the programmed voltage limit.";
CM_ SG_ 2198306822 Phase_W_undervoltage_3 "Indicates an undervoltage event on Phase U. The overvoltage event is triggered when the measured phase voltage is over the programmed voltage limit.";
CM_ SG_ 2198306822 Phase_W_overcurrent_3 "Indicates an overcurrent event on Phase U. The overcurrent event is triggered when the measured phase current is over the programmed current limit.";
CM_ SG_ 2198306822 DC_undervoltage_3 "DC bus undervoltage condition. The undervoltage condition is asserted when the measured dc bus voltage is under the programmed voltage limit.";
CM_ SG_ 2198306822 DC_overvoltage_3 "DC bus overvoltage condition. The overvoltage condition is asserted when the measured dc bus voltage is over the programmed voltage limit.";
CM_ SG_ 2198306822 MOSFET_overtemperature_3 "This flag is asserted when the temperature of the MOSFET block is too high.";
CM_ SG_ 2198306822 Inductor_overtemperature_3 "This flag is asserted when the temperature of the inductor block is too high.";
CM_ SG_ 2198306822 Keep_Alive_not_served_3 "The Keep Alive feature is enabled but it was not served with the periodic message.";
CM_ SG_ 2198306822 PLL_not_locked_3 "Flag asserted when in rectifier modes, the PLL went out of lock condition";
CM_ SG_ 2198306822 Measurement_system_failure_3 "The voltages/currents measurement system is malfunctionning, and readouts are not guaranteed to be accurate.";
CM_ SG_ 2198306822 EEPROM_failure_3 "The configuration EEPROM failed to load or save the module configuration.";
CM_ SG_ 2198306819 Phase_U_3 "Phase current is the MOSFET loop current, in the branch U of the converter.";
CM_ SG_ 2198306819 Phase_V_3 "Phase current is the MOSFET loop current, in the branch V of the converter.";
CM_ SG_ 2198306819 Phase_W_3 "Phase current is the MOSFET loop current, in the branch W of the converter.";
CM_ SG_ 2198306832 Bus_current_3 "DC Bus current is possitive when current goes from input to output";
CM_ SG_ 2198306830 Phase_U_3 "Phase current is the MOSFET loop current, in the branch U of the converter.";
CM_ SG_ 2198306830 Phase_V_3 "Phase current is the MOSFET loop current, in the branch V of the converter.";
CM_ SG_ 2198306830 Phase_W_3 "Phase current is the MOSFET loop current, in the branch W of the converter.";
CM_ SG_ 2198306830 Stack_position_3 "Sender Stack position";
CM_ SG_ 2198306830 Group_ID_3 "Sender Group ID";
CM_ SG_ 2198306827 Phase_U_3 "RMS Phase current is the MOSFET loop current, in the branch U of the converter.";
CM_ SG_ 2198306827 Phase_V_3 "RMS Phase current is the MOSFET loop current, in the branch V of the converter.";
CM_ SG_ 2198306827 Phase_W_3 "RMS Phase current is the MOSFET loop current, in the branch W of the converter.";
CM_ SG_ 2198306828 Frequency_3 "Frequency of Three-Phase system";
CM_ SG_ 2198306828 Phase_3 "Phase of Three-Phase system";
CM_ SG_ 2198306821 Temp_Bridge_3 "Temperature of the MOSFET block";
CM_ SG_ 2198306821 Temp_Inductors_3 "Temperature of the inductors";
CM_ SG_ 2198306824 Phase_U_3 "The actual PWM duty cycle setpoint";
CM_ SG_ 2198306824 Phase_V_3 "The actual PWM duty cycle setpoint";
CM_ SG_ 2198306824 Phase_W_3 "The actual PWM duty cycle setpoint";
CM_ SG_ 2198306825 Current_setpoint_3 "The actual current setpoint";
CM_ SG_ 2198306825 Voltage_setpoint_3 "The actual voltage setpoint";
CM_ SG_ 2198306825 Frequency_setpoint_3 "The actual frequency setpoint";
CM_ SG_ 2198274144 Keep_Alive_Enable_3 "If set to 1, module will expect to receive this message every second repeatedly, or it will stop operation";
CM_ SG_ 2198274112 Converter_ON_3 "Enable the converter.";
CM_ SG_ 2198274112 PWM_ON_3 "Enable the PWM control mode.";
CM_ SG_ 2198274112 DC_Current_feedback_ON_3 "Enable the DC current loop";
CM_ SG_ 2198274112 AC_Current_feedback_ON_3 "Enable the AC current loop";
CM_ SG_ 2198274112 Buck_ON_3 "Enable the buck control mode.";
CM_ SG_ 2198274112 Boost_ON_3 "Enable the boost control mode.";
CM_ SG_ 2198274112 Rectifier_3ph_ON_3 "Enable the three-phase rectifier control mode.";
CM_ SG_ 2198274112 Inverter_1ph_ON_3 "Enable the single-phase inverter control mode.";
CM_ SG_ 2198274112 Rectifier_1ph_ON_3 "Enable the single-phase rectifier control mode.";
CM_ SG_ 2198274112 Boost_Neutral_ON_3 "Enable the boost control mode with neutral generation.";
CM_ SG_ 2198274112 Inverter_3ph_ON_3 "Enable the three-phase inverter control mode.";
CM_ SG_ 2198274112 Inverter_1ph_Sync_ON_3 "Single-phase inverter control mode with phase synchronization.";
CM_ SG_ 2198274112 Neutral_ON_3 "Open-loop neutral generation.";
CM_ SG_ 2198274112 Rectifier_1ph_Buck_ON_3 "Single-phase rectifier with buck on one leg.";
CM_ SG_ 2198274112 Inverter_1ph_Boost_ON_3 "Single-phase inverter with boost on one leg.";
CM_ SG_ 2198274112 Rectifier_Distributed_ON_3 "Single-phase (floating) distributed rectifier";
CM_ SG_ 2198274112 MPPT_buck_ON_3 "MPPT buck";
CM_ SG_ 2198274112 MPPT_boost_ON_3 "MPPT boost";
CM_ SG_ 2198274112 Buck_2p_float_ON_3 "Boost on L1 and L2. Floating L3 (high-impedance)";
CM_ SG_ 2198274112 Inverter_1ph_Distributed_ON_3 "Single-phase inverter mode distributed";
CM_ SG_ 2198274128 Clear_Interlock_3 "Clears the converter interlock";
CM_ SG_ 2198274128 Reset_Processor_3 "Reset the converter DSP";
CM_ SG_ 2198274128 Trip_Interlock_3 "Trip the inetrnal Interlock";
CM_ SG_ 2198274113 Reactive_current_setpoint_3 "This defines reactive current setpoint for 3-phase rectifier mode";
CM_ SG_ 2198274114 Phase_U_3 "The actual PWM duty cycle setpoint";
CM_ SG_ 2198274114 Phase_V_3 "The actual PWM duty cycle setpoint";
CM_ SG_ 2198274114 Phase_W_3 "The actual PWM duty cycle setpoint";
CM_ SG_ 2198274115 Current_setpoint_3 "Sets the output current setpoint. Active only when the current loop is enabled";
CM_ SG_ 2198274116 Voltage_setpoint_3 "Sets the output voltage setpoint. Active only when the voltage loop is enabled";
CM_ SG_ 2198274120 Frequency_setpoint_3 "Sets the frequency for single-phase and three-phase generator modes.";
CM_ SG_ 2198274121 Phase_setpoint_3 "Sets the phase for inverter control modes.";
CM_ SG_ 2198274117 Stack_position_3 "The converter position within the stack";
CM_ SG_ 2198274117 Stack_size_3 "How many PFC converters are in stack in total";
CM_ SG_ 2198274117 SN_number_3 "Unique module serial number";
CM_ SG_ 2198274096 Phase_voltage_min_3 "Minimum tolerated phase voltage";
CM_ SG_ 2198274096 Phase_voltage_max_3 "Maximum allowable phase voltage";
CM_ SG_ 2198274096 DC_voltage_min_3 "Minimum allowable dc voltage";
CM_ SG_ 2198274096 DC_voltage_max_3 "Maximum allowable dc voltage";
CM_ SG_ 2198274097 Phase_current_min_3 "Minimum allowable output current";
CM_ SG_ 2198274097 Phase_current_max_3 "Maximum allowable output current";
CM_ SG_ 2198274124 Group_ID_3 "Desired group ID for the device";
CM_ SG_ 2198306831 Group_ID_3 "Group ID of the device";
CM_ SG_ 2198274145 Factory_mode_3 "Customers MUST NOT USE this bit. If set to 1, module will enter in factory mode. ";
CM_ SG_ 2198274145 Silent_CAN_mode_3 "Customers MUST NOT USE this bit. If set to 1, module will enter in factory mode. ";
CM_ SG_ 2198274122 start_3 "Start automatic calibration. Multiplexer index must be 0!";
CM_ SG_ 2198274123 point_3 "Calibration point index.";
CM_ SG_ 2198274118 CRC_3 "Checksum of bytes 0 to 3, CRC-CCITT, corresponding to qChecksum (www.qt.io)";
CM_ SG_ 2198274119 CRC_3 "Checksum of bytes 0 to 3, CRC-CCITT, corresponding to qChecksum (www.qt.io)";
CM_ SG_ 2198306902 Current_U_High_3 "This flag is set if a hight current on U tripped the internal interlock";
CM_ SG_ 2198306902 Current_U_Low_3 "This flag is set if a low current on U tripped the internal interlock";
CM_ SG_ 2198306902 Current_V_High_3 "This flag is set if a hight current on V tripped the internal interlock";
CM_ SG_ 2198306902 Current_V_Low_3 "This flag is set if a low current on V tripped the internal interlock";
CM_ SG_ 2198306902 Current_W_High_3 "This flag is set if a hight current on W tripped the internal interlock";
CM_ SG_ 2198306902 Current_W_Low_3 "This flag is set if a low current on W tripped the internal interlock";
CM_ SG_ 2198306902 Voltage_DC_3 "This flag is set if a voltage on DC tripped the internal interlock";
CM_ SG_ 2198306902 Reboot_3 "This flag is set if a reboot tripped the internal interlock";
CM_ SG_ 2198306902 Unknown_3 "This flag the reason for the internal interlock is unknown";

BA_DEF_ BO_ "SystemMessageLongSymbol" STRING;

BA_ "SystemMessageLongSymbol" BO_ 2198274113 "AFE_Reactive_Current_Setpoint_Control_3";

VAL_ 2198306816 Device_type_3 7 "AFE";
VAL_ 2198306822 Protection_trip_internal_3 1 "fault";
VAL_ 2198306822 Protection_trip_external_3 1 "fault";
VAL_ 2198306822 Phase_U_overcurrent_3 1 "fault";
VAL_ 2198306822 Phase_U_overvoltage_3 1 "fault";
VAL_ 2198306822 Phase_U_undervoltage_3 1 "fault";
VAL_ 2198306822 Phase_V_overvoltage_3 1 "fault";
VAL_ 2198306822 Phase_V_undervoltage_3 1 "fault";
VAL_ 2198306822 Phase_V_overcurrent_3 1 "fault";
VAL_ 2198306822 Phase_W_overvoltage_3 1 "fault";
VAL_ 2198306822 Phase_W_undervoltage_3 1 "fault";
VAL_ 2198306822 Phase_W_overcurrent_3 1 "fault";
VAL_ 2198306822 DC_undervoltage_3 1 "fault";
VAL_ 2198306822 DC_overvoltage_3 1 "fault";
VAL_ 2198306822 MOSFET_overtemperature_3 1 "fault";
VAL_ 2198306822 Inductor_overtemperature_3 1 "fault";
VAL_ 2198306822 Keep_Alive_not_served_3 1 "fault";
VAL_ 2198306822 PLL_not_locked_3 1 "fault";
VAL_ 2198306822 NFO_3 1 "fault";
VAL_ 2198306822 Measurement_system_failure_3 1 "fault";
VAL_ 2198306822 EEPROM_failure_3 1 "fault";
VAL_ 2198306822 System_3 1 "fault";
VAL_ 2198306902 Current_U_High_3 1 "fault";
VAL_ 2198306902 Current_U_Low_3 1 "fault";
VAL_ 2198306902 Current_V_High_3 1 "fault";
VAL_ 2198306902 Current_V_Low_3 1 "fault";
VAL_ 2198306902 Current_W_High_3 1 "fault";
VAL_ 2198306902 Current_W_Low_3 1 "fault";
VAL_ 2198306902 Voltage_DC_3 1 "fault";
VAL_ 2198306902 Reboot_3 1 "fault";
VAL_ 2198306902 Unknown_3 1 "fault";
SIG_VALTYPE_ 2198306897 Current_U_3 : 1;
SIG_VALTYPE_ 2198306897 Current_V_3 : 1;
SIG_VALTYPE_ 2198306897 Current_W_3 : 1;
SIG_VALTYPE_ 2198306897 Voltage_U_3 : 1;
SIG_VALTYPE_ 2198306897 Voltage_V_3 : 1;
SIG_VALTYPE_ 2198306897 Voltage_W_3 : 1;
SIG_VALTYPE_ 2198306897 Voltage_DC_3 : 1;
SIG_VALTYPE_ 2198306898 Current_U_3 : 1;
SIG_VALTYPE_ 2198306898 Current_V_3 : 1;
SIG_VALTYPE_ 2198306898 Current_W_3 : 1;
SIG_VALTYPE_ 2198306898 Voltage_U_3 : 1;
SIG_VALTYPE_ 2198306898 Voltage_V_3 : 1;
SIG_VALTYPE_ 2198306898 Voltage_W_3 : 1;
SIG_VALTYPE_ 2198306898 Voltage_DC_3 : 1;
